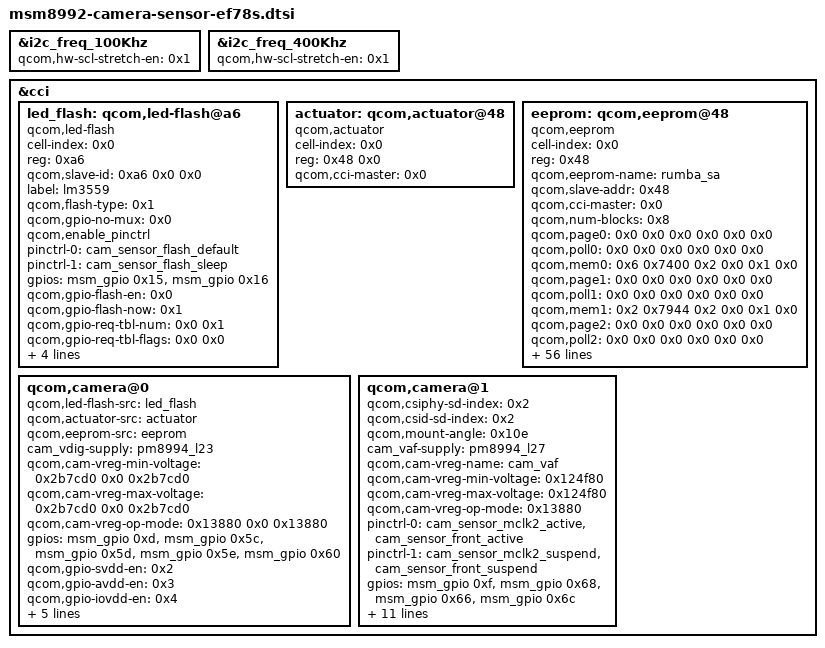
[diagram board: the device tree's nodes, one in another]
/*
 * Copyright (c) 2015, The Linux Foundation. All rights reserved.
 *
 * This program is free software; you can redistribute it and/or modify
 * it under the terms of the GNU General Public License version 2 and
 * only version 2 as published by the Free Software Foundation.
 *
 * This program is distributed in the hope that it will be useful,
 * but WITHOUT ANY WARRANTY; without even the implied warranty of
 * MERCHANTABILITY or FITNESS FOR A PARTICULAR PURPOSE.  See the
 * GNU General Public License for more details.
 */

/* Pantech EF78S camera sensors, actuator, EEPROM and LED flash */

&i2c_freq_100Khz {
	qcom,hw-scl-stretch-en = <0x1>;
};

&i2c_freq_400Khz {
	qcom,hw-scl-stretch-en = <0x1>;
};

&cci {

	led_flash: qcom,led-flash@a6 {
		cell-index = <0x0>;
		reg = <0xa6>;
		qcom,slave-id = <0xa6 0x0 0x0>;
		compatible = "qcom,led-flash";
		label = "lm3559";
		qcom,flash-type = <0x1>;
		qcom,gpio-no-mux = <0x0>;
		qcom,enable_pinctrl;
		pinctrl-names = "cam_flash_default", "cam_flash_suspend";
		pinctrl-0 = <&cam_sensor_flash_default>;
		pinctrl-1 = <&cam_sensor_flash_sleep>;
		gpios = <&msm_gpio 0x15 0x0 &msm_gpio 0x16 0x0>;
		qcom,gpio-flash-en = <0x0>;
		qcom,gpio-flash-now = <0x1>;
		qcom,gpio-req-tbl-num = <0x0 0x1>;
		qcom,gpio-req-tbl-flags = <0x0 0x0>;
		qcom,gpio-req-tbl-label = "FLASH_EN", "FLASH_NOW";
		qcom,cci-master = <0x0>;
		qcom,max-current = <0x3e8>;
		qcom,max-duration = <0x3e8>;
	};

	actuator: qcom,actuator@48 {
		cell-index = <0x0>;
		reg = <0x48 0x0>;
		compatible = "qcom,actuator";
		qcom,cci-master = <0x0>;
	};

	eeprom: qcom,eeprom@48 {
		cell-index = <0x0>;
		reg = <0x48>;
		qcom,eeprom-name = "rumba_sa";
		compatible = "qcom,eeprom";
		qcom,slave-addr = <0x48>;
		qcom,cci-master = <0x0>;
		qcom,num-blocks = <0x8>;
		qcom,page0 = <0x0 0x0 0x0 0x0 0x0 0x0>;
		qcom,poll0 = <0x0 0x0 0x0 0x0 0x0 0x0>;
		qcom,mem0 = <0x6 0x7400 0x2 0x0 0x1 0x0>;
		qcom,page1 = <0x0 0x0 0x0 0x0 0x0 0x0>;
		qcom,poll1 = <0x0 0x0 0x0 0x0 0x0 0x0>;
		qcom,mem1 = <0x2 0x7944 0x2 0x0 0x1 0x0>;
		qcom,page2 = <0x0 0x0 0x0 0x0 0x0 0x0>;
		qcom,poll2 = <0x0 0x0 0x0 0x0 0x0 0x0>;
		qcom,mem2 = <0x374 0x7406 0x2 0x0 0x1 0x0>;
		qcom,page3 = <0x0 0x0 0x0 0x0 0x0 0x0>;
		qcom,poll3 = <0x0 0x0 0x0 0x0 0x0 0x0>;
		qcom,mem3 = <0x2 0x7946 0x2 0x0 0x1 0x0>;
		qcom,page4 = <0x0 0x0 0x0 0x0 0x0 0x0>;
		qcom,poll4 = <0x0 0x0 0x0 0x0 0x0 0x0>;
		qcom,mem4 = <0x2 0x793c 0x2 0x0 0x1 0x0>;
		qcom,page5 = <0x0 0x0 0x0 0x0 0x0 0x0>;
		qcom,poll5 = <0x0 0x0 0x0 0x0 0x0 0x0>;
		qcom,mem5 = <0x0 0x0 0x0 0x0 0x0 0x0>;
		qcom,page6 = <0x0 0x0 0x0 0x0 0x0 0x0>;
		qcom,poll6 = <0x0 0x0 0x0 0x0 0x0 0x0>;
		qcom,mem6 = <0x2 0x7940 0x2 0x0 0x1 0x0>;
		qcom,page7 = <0x0 0x0 0x0 0x0 0x0 0x0>;
		qcom,poll7 = <0x0 0x0 0x0 0x0 0x0 0x0>;
		qcom,mem7 = <0x0 0x0 0x0 0x0 0x0 0x0>;
		cam_vdig-supply = <&pm8994_l23>;
		cam_vio-supply = <&pm8994_lvs1>;
		cam_vana-supply = <&pm8994_l17>;
		qcom,cam-vreg-name = "cam_vdig", "cam_vio", "cam_vana";
		qcom,cam-vreg-min-voltage = <0x2b7cd0 0x0 0x2b7cd0>;
		qcom,cam-vreg-max-voltage = <0x2b7cd0 0x0 0x2b7cd0>;
		qcom,cam-vreg-op-mode = <0x13880 0x0 0x13880>;
		qcom,gpio-no-mux = <0x0>;
		pinctrl-names = "cam_default", "cam_suspend";
		pinctrl-0 = <&cam_sensor_mclk0_active &cam_sensor_rear_active>;
		pinctrl-1 = <&cam_sensor_mclk0_suspend &cam_sensor_rear_suspend>;
		gpios = <&msm_gpio 0xd 0x0 &msm_gpio 0x5c 0x0 &msm_gpio 0x5d 0x0 &msm_gpio 0x5e 0x0 &msm_gpio 0x60 0x0>;
		qcom,gpio-reset = <0x1>;
		qcom,gpio-svdd-en = <0x2>;
		qcom,gpio-avdd-en = <0x3>;
		qcom,gpio-iovdd-en = <0x4>;
		qcom,gpio-req-tbl-num = <0x0 0x1 0x2 0x3 0x4>;
		qcom,gpio-req-tbl-flags = <0x1 0x0 0x0 0x0 0x0>;
		qcom,gpio-req-tbl-label = "CAMIF_MCLK0", "CAM_RESET0", "CAM_SVDD0_EN", "CAM_AVDD0_EN", "CAM_IOVDD0_EN";
		qcom,cam-power-seq-type = "sensor_vreg", "sensor_gpio", "sensor_vreg", "sensor_vreg", "sensor_gpio", "sensor_gpio", "sensor_gpio", "sensor_clk";
		qcom,cam-power-seq-val = "cam_vdig", "sensor_gpio_avdd_en", "cam_vana", "cam_vio", "sensor_gpio_iovdd_en", "sensor_gpio_svdd_en", "sensor_gpio_reset", "sensor_cam_mclk";
		qcom,cam-power-seq-cfg-val = <0x1 0x1 0x1 0x1 0x1 0x1 0x1 0x16e3600>;
		qcom,cam-power-seq-delay = <0x5 0x5 0x5 0x5 0x5 0x1e 0x1e 0x5>;
		status = "ok";
		clocks = <&clock_mmss 0x266b3853 &clock_mmss 0xcf0c61e0>;
		clock-names = "cam_src_clk", "cam_clk";
	};

	qcom,camera@0 {
		qcom,led-flash-src = <&led_flash>;
		qcom,actuator-src = <&actuator>;
		qcom,eeprom-src = <&eeprom>;
		cam_vdig-supply = <&pm8994_l23>;
		qcom,cam-vreg-min-voltage = <0x2b7cd0 0x0 0x2b7cd0>;
		qcom,cam-vreg-max-voltage = <0x2b7cd0 0x0 0x2b7cd0>;
		qcom,cam-vreg-op-mode = <0x13880 0x0 0x13880>;
		gpios = <&msm_gpio 0xd 0x0 &msm_gpio 0x5c 0x0 &msm_gpio 0x5d 0x0 &msm_gpio 0x5e 0x0 &msm_gpio 0x60 0x0>;
		qcom,gpio-svdd-en = <0x2>;
		qcom,gpio-avdd-en = <0x3>;
		qcom,gpio-iovdd-en = <0x4>;
		qcom,gpio-req-tbl-num = <0x0 0x1 0x2 0x3 0x4>;
		qcom,gpio-req-tbl-flags = <0x1 0x0 0x0 0x0 0x0>;
		qcom,gpio-req-tbl-label = "CAMIF_MCLK0", "CAM_RESET0", "CAM_SVDD0_EN", "CAM_AVDD0_EN", "CAM_IOVDD0_EN";
		/delete-property/ qcom,ois-src;
		/delete-property/ qcom,gpio-standby;
	};

	qcom,camera@1 {
		qcom,csiphy-sd-index = <0x2>;
		qcom,csid-sd-index = <0x2>;
		qcom,mount-angle = <0x10e>;
		cam_vaf-supply = <&pm8994_l27>;
		qcom,cam-vreg-name = "cam_vaf";
		qcom,cam-vreg-min-voltage = <0x124f80>;
		qcom,cam-vreg-max-voltage = <0x124f80>;
		qcom,cam-vreg-op-mode = <0x13880>;
		pinctrl-0 = <&cam_sensor_mclk2_active &cam_sensor_front_active>;
		pinctrl-1 = <&cam_sensor_mclk2_suspend &cam_sensor_front_suspend>;
		gpios = <&msm_gpio 0xf 0x0 &msm_gpio 0x68 0x0 &msm_gpio 0x66 0x0 &msm_gpio 0x6c 0x0>;
		qcom,gpio-avdd-en = <0x2>;
		qcom,gpio-svdd-en = <0x3>;
		qcom,gpio-req-tbl-num = <0x0 0x1 0x2 0x3>;
		qcom,gpio-req-tbl-flags = <0x1 0x0 0x0 0x0>;
		qcom,gpio-req-tbl-label = "CAMIF_MCLK2", "CAM_RESET2", "CAM_AVDD1_EN", "CAM_SVDD1_EN";
		qcom,sensor-position = <0x1>;
		qcom,sensor-mode = <0x1>;
		qcom,cci-master = <0x1>;
		clocks = <&clock_mmss 0x42545468 &clock_mmss 0x851286f2>;
		/delete-property/ cam_vdig-supply;
		/delete-property/ cam_vio-supply;
		/delete-property/ cam_vana-supply;
		/delete-property/ qcom,gpio-standby;
	};
	/delete-node/ qcom,actuator@0;
	/delete-node/ qcom,actuator@1;
	/delete-node/ qcom,ois@0;
	/delete-node/ qcom,eeprom@0;
	/delete-node/ qcom,eeprom@1;
	/delete-node/ qcom,eeprom@2;
	/delete-node/ qcom,camera@2;
};
